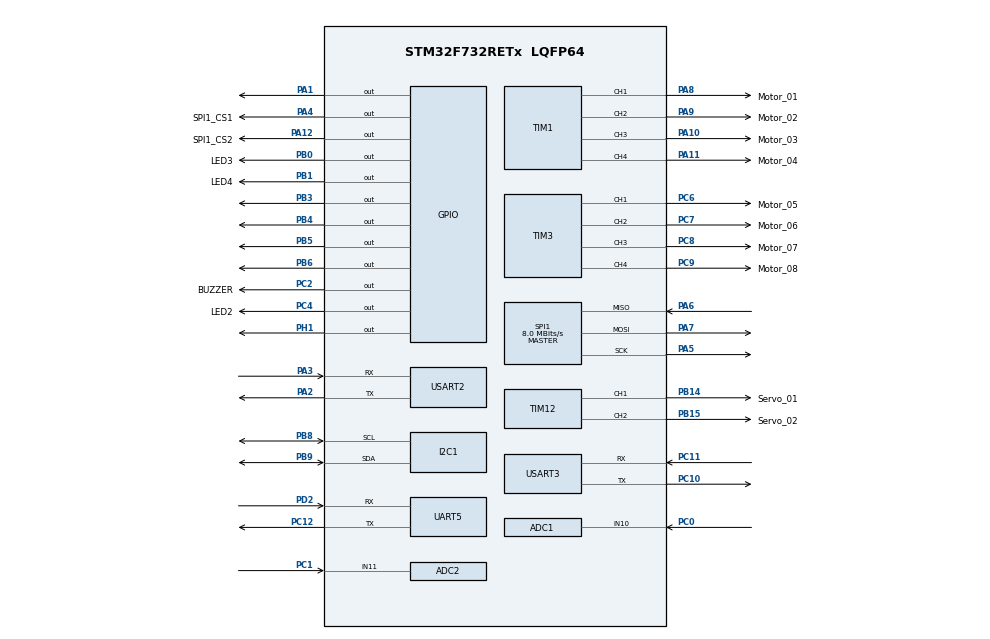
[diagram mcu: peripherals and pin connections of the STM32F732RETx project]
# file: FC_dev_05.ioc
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ADC1.Channel-1\#ChannelRegularConversion=ADC_CHANNEL_10
ADC1.NbrOfConversionFlag=1
ADC1.Rank-1\#ChannelRegularConversion=1
ADC1.SamplingTime-1\#ChannelRegularConversion=ADC_SAMPLETIME_3CYCLES
ADC1.master=1
ADC2.Channel-0\#ChannelRegularConversion=ADC_CHANNEL_11
ADC2.NbrOfConversionFlag=1
ADC2.Rank-0\#ChannelRegularConversion=1
ADC2.SamplingTime-0\#ChannelRegularConversion=ADC_SAMPLETIME_3CYCLES
CORTEX_M7.default_mode_Activation=1
Mcu.Family=STM32F7
Mcu.Name=STM32F732RETx
Mcu.Package=LQFP64
NVIC.PriorityGroup=NVIC_PRIORITYGROUP_4
PA1.Signal=GPIO_Output
PA10.GPIO_Label=Motor_03
PA10.Signal=S_TIM1_CH3
PA11.GPIO_Label=Motor_04
PA11.Signal=S_TIM1_CH4
PA12.GPIO_Label=SPI1_CS2
PA12.Signal=GPIO_Output
PA13.Signal=SYS_JTMS-SWDIO
PA14.Signal=SYS_JTCK-SWCLK
PA2.Mode=Asynchronous
PA2.Signal=USART2_TX
PA3.Mode=Asynchronous
PA3.Signal=USART2_RX
PA4.GPIO_Label=SPI1_CS1
PA4.Signal=GPIO_Output
PA5.Mode=Full_Duplex_Master
PA5.Signal=SPI1_SCK
PA6.Mode=Full_Duplex_Master
PA6.Signal=SPI1_MISO
PA7.Mode=Full_Duplex_Master
PA7.Signal=SPI1_MOSI
PA8.GPIO_Label=Motor_01
PA8.Signal=S_TIM1_CH1
PA9.GPIO_Label=Motor_02
PA9.Signal=S_TIM1_CH2
PB0.GPIO_Label=LED3
PB0.Signal=GPIO_Output
PB1.GPIO_Label=LED4
PB1.Signal=GPIO_Output
PB14.GPIO_Label=Servo_01
PB14.Signal=S_TIM12_CH1
PB15.GPIO_Label=Servo_02
PB15.Signal=S_TIM12_CH2
PB3.Signal=GPIO_Output
PB4.Signal=GPIO_Output
PB5.Signal=GPIO_Output
PB6.Signal=GPIO_Output
PB8.Mode=I2C
PB8.Signal=I2C1_SCL
PB9.Mode=I2C
PB9.Signal=I2C1_SDA
PC0.Signal=ADCx_IN10
PC1.Signal=ADCx_IN11
PC10.Mode=Asynchronous
PC10.Signal=USART3_TX
PC11.Mode=Asynchronous
PC11.Signal=USART3_RX
PC12.Mode=Asynchronous
PC12.Signal=UART5_TX
PC2.GPIO_Label=BUZZER
PC2.Signal=GPIO_Output
PC4.GPIO_Label=LED2
PC4.Signal=GPIO_Output
PC6.GPIO_Label=Motor_05
PC6.Signal=S_TIM3_CH1
PC7.GPIO_Label=Motor_06
PC7.Signal=S_TIM3_CH2
PC8.GPIO_Label=Motor_07
PC8.Signal=S_TIM3_CH3
PC9.GPIO_Label=Motor_08
PC9.Signal=S_TIM3_CH4
PD2.Mode=Asynchronous
PD2.Signal=UART5_RX
PH0-OSC_IN.Signal=RCC_OSC_IN
PH1-OSC_OUT.Signal=GPIO_Output
ProjectManager.HeapSize=0x200
ProjectManager.StackSize=0x400
ProjectManager.TargetToolchain=STM32CubeIDE
RCC.HSE_VALUE=25000000
RCC.HSI_VALUE=16000000
RCC.LSE_VALUE=32768
RCC.USBFreq_Value=96000000
RCC.VCOOutputFreq_Value=192000000
SH.ADCx_IN10.0=ADC1_IN10,IN10
SH.ADCx_IN11.0=ADC2_IN11,IN11
SH.S_TIM12_CH1.0=TIM12_CH1,PWM Generation1 CH1
SH.S_TIM12_CH2.0=TIM12_CH2,PWM Generation2 CH2
SH.S_TIM1_CH1.0=TIM1_CH1,PWM Generation1 CH1
SH.S_TIM1_CH2.0=TIM1_CH2,PWM Generation2 CH2
SH.S_TIM1_CH3.0=TIM1_CH3,PWM Generation3 CH3
SH.S_TIM1_CH4.0=TIM1_CH4,PWM Generation4 CH4
SH.S_TIM3_CH1.0=TIM3_CH1,PWM Generation1 CH1
SH.S_TIM3_CH2.0=TIM3_CH2,PWM Generation2 CH2
SH.S_TIM3_CH3.0=TIM3_CH3,PWM Generation3 CH3
SH.S_TIM3_CH4.0=TIM3_CH4,PWM Generation4 CH4
SPI1.CalculateBaudRate=8.0 MBits/s
SPI1.Direction=SPI_DIRECTION_2LINES
SPI1.Mode=SPI_MODE_MASTER
SPI1.VirtualType=VM_MASTER
TIM1.Channel-PWM\ Generation1\ CH1=TIM_CHANNEL_1
TIM1.Channel-PWM\ Generation2\ CH2=TIM_CHANNEL_2
TIM1.Channel-PWM\ Generation3\ CH3=TIM_CHANNEL_3
TIM1.Channel-PWM\ Generation4\ CH4=TIM_CHANNEL_4
TIM12.Channel-PWM\ Generation1\ CH1=TIM_CHANNEL_1
TIM12.Channel-PWM\ Generation2\ CH2=TIM_CHANNEL_2
TIM3.Channel-PWM\ Generation1\ CH1=TIM_CHANNEL_1
TIM3.Channel-PWM\ Generation2\ CH2=TIM_CHANNEL_2
TIM3.Channel-PWM\ Generation3\ CH3=TIM_CHANNEL_3
TIM3.Channel-PWM\ Generation4\ CH4=TIM_CHANNEL_4
TIM6.Period=999
TIM6.Prescaler=107
USART2.VirtualMode-Asynchronous=VM_ASYNC
USART3.VirtualMode-Asynchronous=VM_ASYNC
VP_TIM6_VS_ClockSourceINT.Mode=Enable_Timer
board=custom

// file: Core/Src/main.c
/* USER CODE BEGIN Header */
/**
  ******************************************************************************
  * @file           : main.c
  * @brief          : Main program body
  ******************************************************************************
  * @attention
  *
  * Copyright (c) 2025 STMicroelectronics.
  * All rights reserved.
  *
  * This software is licensed under terms that can be found in the LICENSE file
  * in the root directory of this software component.
  * If no LICENSE file comes with this software, it is provided AS-IS.
  *
  ******************************************************************************
  */
/* USER CODE END Header */
#include "main.h"
#include "adc.h"
#include "i2c.h"
#include "spi.h"
#include "tim.h"
#include "usart.h"
#include "gpio.h"

/* USER CODE BEGIN Includes */
#include "wrapper.hpp"
/* USER CODE END Includes */

void SystemClock_Config(void);
static void MPU_Config(void);

int main(void)
{

  /* MPU Configuration--------------------------------------------------------*/
  MPU_Config();

  /* MCU Configuration--------------------------------------------------------*/

  /* Reset of all peripherals, Initializes the Flash interface and the Systick. */
  HAL_Init();

  /* Configure the system clock */
  SystemClock_Config();

  /* Initialize all configured peripherals */
  MX_GPIO_Init();
  MX_TIM1_Init();
  MX_TIM12_Init();
  MX_TIM3_Init();
  MX_TIM6_Init();
  MX_USART2_UART_Init();
  MX_ADC1_Init();
  MX_ADC2_Init();
  MX_I2C1_Init();
  MX_SPI1_Init();
  MX_UART5_Init();
  MX_USART3_UART_Init();
  /* USER CODE BEGIN 2 */
  init();
  /* USER CODE END 2 */

  /* Infinite loop */
  while (1)
  {

  }
}

void SystemClock_Config(void)
{
  RCC_OscInitTypeDef RCC_OscInitStruct = {0};
  RCC_ClkInitTypeDef RCC_ClkInitStruct = {0};

  /** Configure the main internal regulator output voltage
  */
  __HAL_RCC_PWR_CLK_ENABLE();
  __HAL_PWR_VOLTAGESCALING_CONFIG(PWR_REGULATOR_VOLTAGE_SCALE3);

  /** Initializes the RCC Oscillators according to the specified parameters
  * in the RCC_OscInitTypeDef structure.
  */
  RCC_OscInitStruct.OscillatorType = RCC_OSCILLATORTYPE_HSI;
  RCC_OscInitStruct.HSIState = RCC_HSI_ON;
  RCC_OscInitStruct.HSICalibrationValue = RCC_HSICALIBRATION_DEFAULT;
  RCC_OscInitStruct.PLL.PLLState = RCC_PLL_NONE;
  if (HAL_RCC_OscConfig(&RCC_OscInitStruct) != HAL_OK)
  {
    Error_Handler();
  }

  /** Initializes the CPU, AHB and APB buses clocks
  */
  RCC_ClkInitStruct.ClockType = RCC_CLOCKTYPE_HCLK|RCC_CLOCKTYPE_SYSCLK
                              |RCC_CLOCKTYPE_PCLK1|RCC_CLOCKTYPE_PCLK2;
  RCC_ClkInitStruct.SYSCLKSource = RCC_SYSCLKSOURCE_HSI;
  RCC_ClkInitStruct.AHBCLKDivider = RCC_SYSCLK_DIV1;
  RCC_ClkInitStruct.APB1CLKDivider = RCC_HCLK_DIV1;
  RCC_ClkInitStruct.APB2CLKDivider = RCC_HCLK_DIV1;

  if (HAL_RCC_ClockConfig(&RCC_ClkInitStruct, FLASH_LATENCY_0) != HAL_OK)
  {
    Error_Handler();
  }
}

 /* MPU Configuration */

void MPU_Config(void)
{
  MPU_Region_InitTypeDef MPU_InitStruct = {0};

  /* Disables the MPU */
  HAL_MPU_Disable();

  /** Initializes and configures the Region and the memory to be protected
  */
  MPU_InitStruct.Enable = MPU_REGION_ENABLE;
  MPU_InitStruct.Number = MPU_REGION_NUMBER0;
  MPU_InitStruct.BaseAddress = 0x0;
  MPU_InitStruct.Size = MPU_REGION_SIZE_4GB;
  MPU_InitStruct.SubRegionDisable = 0x87;
  MPU_InitStruct.TypeExtField = MPU_TEX_LEVEL0;
  MPU_InitStruct.AccessPermission = MPU_REGION_NO_ACCESS;
  MPU_InitStruct.DisableExec = MPU_INSTRUCTION_ACCESS_DISABLE;
  MPU_InitStruct.IsShareable = MPU_ACCESS_SHAREABLE;
  MPU_InitStruct.IsCacheable = MPU_ACCESS_NOT_CACHEABLE;
  MPU_InitStruct.IsBufferable = MPU_ACCESS_NOT_BUFFERABLE;

  HAL_MPU_ConfigRegion(&MPU_InitStruct);
  /* Enables the MPU */
  HAL_MPU_Enable(MPU_PRIVILEGED_DEFAULT);

}

void Error_Handler(void)
{
  __disable_irq();
  while (1)
  {
  }
}
